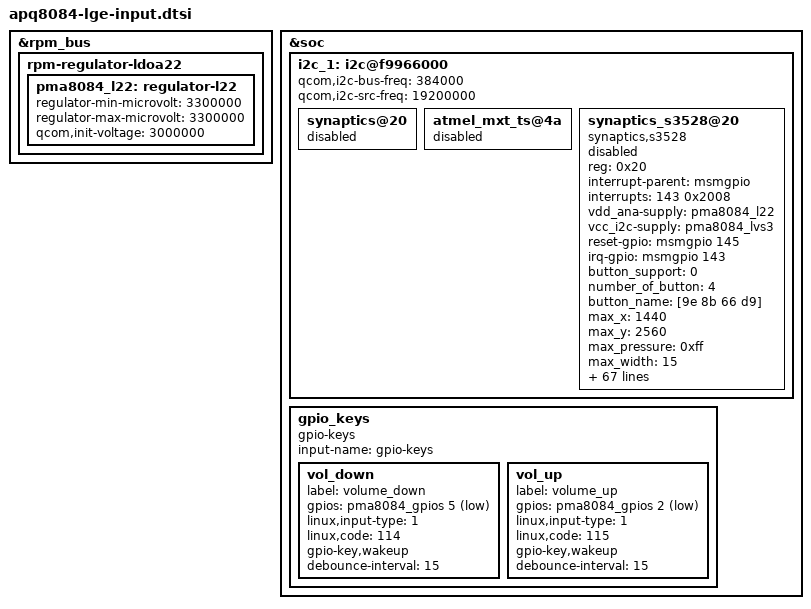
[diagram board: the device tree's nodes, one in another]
/* Copyright (c) 2012, Code Aurora Forum. All rights reserved.
 *
 * This program is free software; you can redistribute it and/or modify
 * it under the terms of the GNU General Public License version 2 and
 * only version 2 as published by the Free Software Foundation.
 *
 * This program is distributed in the hope that it will be useful,
 * but WITHOUT ANY WARRANTY; without even the implied warranty of
 * MERCHANTABILITY or FITNESS FOR A PARTICULAR PURPOSE.  See the
 * GNU General Public License for more details.
 */

&rpm_bus {
	rpm-regulator-ldoa22 {
		status = "okay";
		pma8084_l22: regulator-l22 {
			regulator-min-microvolt = <3300000>;
			regulator-max-microvolt = <3300000>;
			qcom,init-voltage = <3000000>;
			status = "okay";
		};
	};
};

&soc {
	i2c_1: i2c@f9966000 {
	       qcom,i2c-bus-freq = <384000>;
	       qcom,i2c-src-freq = <19200000>;
	};

	i2c@f9966000 {
		synaptics@20 {
			status = "disable";
		};

		atmel_mxt_ts@4a {
			status = "disable";
		};

		synaptics_s3528@20 {
			compatible = "synaptics,s3528";
			status = "disable";
			reg = <0x20>;
			interrupt-parent = <&msmgpio>;
			interrupts = <143 0x2008>;
			vdd_ana-supply = <&pma8084_l22>;
			vcc_i2c-supply = <&pma8084_lvs3>;
			reset-gpio = <&msmgpio 145 0x00>;
			irq-gpio = <&msmgpio 143 0x2008>;

			/*Caps*/
			button_support = <0>;
			number_of_button = <4>;
			button_name = [9e 8b 66 d9];
			max_x = <1440>;
			max_y = <2560>;
			max_pressure = <0xff>;
			max_width = <15>;
			max_orientation = <1>;
			max_id = <10>;
			/*role*/
			protocol_type = <1>;
			report_mode = <0>;
			delta_pos_threshold = <1>;
			report_period = <10000000>;
			booting_delay = <80>;
			reset_delay = <10>;
			wake_up_by_touch = <1>;
			use_sleep_mode = <1>;
			thermal_check = <1>;
			palm_ctrl_mode = <0>;
			mini_os_finger_amplitude = <41>;
			irqflags = <0x00000002>;
			bouncing.enable = <0>;
			grip.enable = <0>;
			grip.edge_region = <5>;
			grip.max_delta = <10>;
			grip.width_ratio = <2>;
			accuracy.enable = <0>;
			accuracy.min_delta = <3>;
			accuracy.curr_ratio = <5>;
			accuracy.min_pressure = <50>;
			jitter.enable = <0>;
			jitter.curr_ratio = <115>;
			quickcover.enable = <1>;
			quickcover.X1 = <148>;
			quickcover.X2 = <1292>;
			quickcover.Y1 = <0>;
			quickcover.Y2 = <1101>;
			crack.enable = <1>;
			crack.min.cap = <300>;
			/*ghost_detection -S*/
			ghost_detection_enable = <1>;
			ghost_detection_chk_cnt = <3>;
			jitter_value = <20>;
			ta_noise_chk = <0>;
			incoming_call_chk = <0>;
			first_finger_chk = <1>;
			first_finger_time = <200>;
			pressure_zero_chk = <1>;
			ta_debouncing_chk = <0>;
			ta_debouncing_cnt = <2>;
			ta_debouncing_finger_num = <2>;
			press_interval_chk = <1>;
			press_interval = <29>;
			diff_fingers_chk = <1>;
			diff_finger_num = <5>;
			subtraction_finger_chk = <0>;
			subtraction_time = <11>;
			subtraction_finger_cnt = <5>;
			long_press_chk = <1>;
			long_press_chk_time = <10>;
			long_press_cnt = <700>;
			button_chk = <0>;
			button_int_num = <6>;
			button_duration = <100>;
			rebase_repetition_chk = <1>;
			rebase_since_init = <3>;
			rebase_since_rebase = <5>;
			use_lpwg_all = <1>;
			use_security_mode = <1>;
			/*ghost_detection -E*/
			/*pwr*/
			use_regulator = <1>;
			vdd = "vdd_ana";
			vdd_voltage = <3300000>;
			vio = "vcc_i2c";
			vio_voltage = <0>;
			/*firmware*/
			need_upgrade = <1>;
		};
	};

	gpio_keys {
		compatible = "gpio-keys";
		input-name = "gpio-keys";

		/delete-node/ camera_focus;
		/delete-node/ camera_snapshot;

		vol_down {
			label = "volume_down";
			gpios = <&pma8084_gpios 5 0x1>;
			linux,input-type = <1>;
			linux,code = <114>;
			gpio-key,wakeup;
			debounce-interval = <15>;
		};

		vol_up {
			label = "volume_up";
			gpios = <&pma8084_gpios 2 0x1>;
			linux,input-type = <1>;
			linux,code = <115>;
			gpio-key,wakeup;
			debounce-interval = <15>;
		};
	};
};
